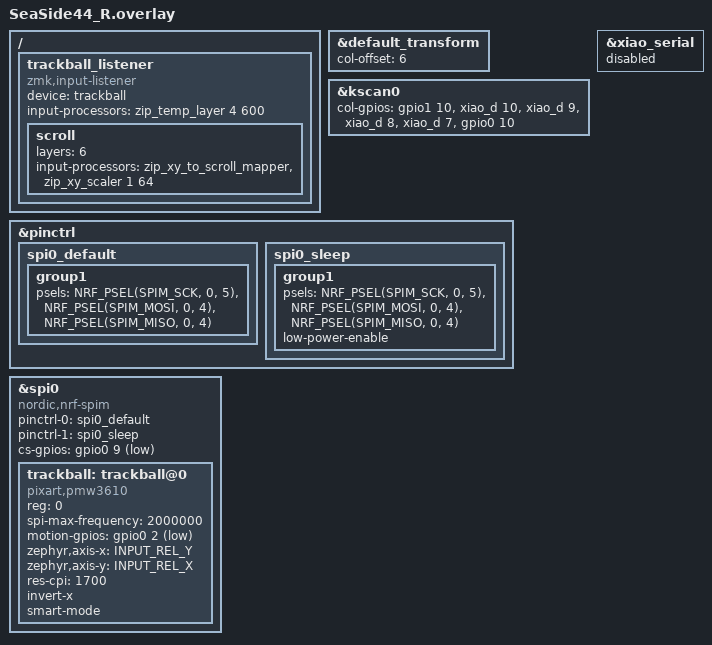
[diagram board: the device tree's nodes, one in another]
#include "SeaSide44.dtsi"
#include <zephyr/dt-bindings/input/input-event-codes.h>
#include <input/processors.dtsi>

&default_transform {
    col-offset = <6>;
};

/* キーマトリクスの設定 */
// 上が外側、下が内側カラムcol番号と実際の配置が直感と逆になってる
&kscan0 {
        col-gpios
            = <&gpio1 10 GPIO_ACTIVE_HIGH>
            , <&xiao_d 10 GPIO_ACTIVE_HIGH>
            , <&xiao_d 9 GPIO_ACTIVE_HIGH> 
            , <&xiao_d 8 GPIO_ACTIVE_HIGH> 
            , <&xiao_d 7 GPIO_ACTIVE_HIGH> 
            , <&gpio0 10 GPIO_ACTIVE_HIGH>
            ;
};

/* Trackball のリスナー */
/ {
    trackball_listener {
        compatible = "zmk,input-listener";
        device = <&trackball>;
        /* オートマウスレイヤー: レイヤー4を600ms有効化 */
        input-processors = <&zip_temp_layer 4 600>;

        /* スクロールレイヤー: レイヤー6でスクロールモードに切り替え */
        scroll {
            layers = <6>;
            /* スクロール変換 + 感度調整 (1/64に減速: multiplier=1, divisor=64) */
            input-processors = <&zip_xy_to_scroll_mapper>, <&zip_xy_scaler 1 64>;
        };
    };
};

/* SPI 設定 */
&pinctrl {
    spi0_default: spi0_default {
        group1 {
            psels = <NRF_PSEL(SPIM_SCK, 0, 5)>,
                <NRF_PSEL(SPIM_MOSI, 0, 4)>,
                <NRF_PSEL(SPIM_MISO, 0, 4)>;
        };
    };

    spi0_sleep: spi0_sleep {
        group1 {
            psels = <NRF_PSEL(SPIM_SCK, 0, 5)>,
                <NRF_PSEL(SPIM_MOSI, 0, 4)>,
                <NRF_PSEL(SPIM_MISO, 0, 4)>;
            low-power-enable;
        };
    };
};

/* シリアルを無効化 */
&xiao_serial { status = "disabled"; };

/* SPI デバイス (トラックボール) */
&spi0 {
    status = "okay";
    compatible = "nordic,nrf-spim";
    pinctrl-0 = <&spi0_default>;
    pinctrl-1 = <&spi0_sleep>;
    pinctrl-names = "default", "sleep";
    cs-gpios = <&gpio0 9 GPIO_ACTIVE_LOW>;

    trackball: trackball@0 {
        status = "okay";
        compatible = "pixart,pmw3610";
        reg = <0>;
        spi-max-frequency = <2000000>;
        motion-gpios = <&gpio0 2 (GPIO_ACTIVE_LOW | GPIO_PULL_UP)>;
        /* 軸入れ替え: センサーのX→画面のY、センサーのY→画面のX */
        zephyr,axis-x = <INPUT_REL_Y>;
        zephyr,axis-y = <INPUT_REL_X>;
        /* CPI 設定 */
        res-cpi = <1700>;
        /* 反転設定: Y軸のみ反転 */
        invert-x;
        /* スマートアルゴリズム (以前の CONFIG_PMW3610_SMART_ALGORITHM=y 相当) */
        smart-mode;
    };
};

